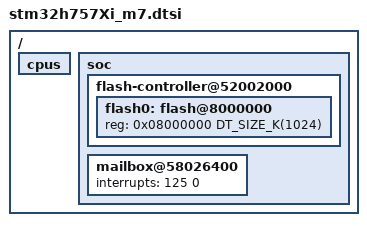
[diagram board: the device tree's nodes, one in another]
/*
 * Copyright (c) 2024 Grinn sp. z o.o.
 *
 * SPDX-License-Identifier: Apache-2.0
 */

#include <st/h7/stm32h757.dtsi>

/delete-node/ &flash1;

/ {
	cpus {
		/delete-node/ cpu@1;
	};

	soc {
		flash-controller@52002000 {
			flash0: flash@8000000 {
				reg = <0x08000000 DT_SIZE_K(1024)>;
			};
		};

		mailbox@58026400 {
			interrupts = <125 0>;
		};
	};
};
